# ISD91200B_v1 register map
File version: 1.0
Registers are 32-bit, read-write, reset 0x0 unless marked. A register's access mark holds for its fields unless they carry their own. Offsets are from the block's base; [hi:lo] are bit positions.

## FMC — FMC Register Map
Base 0x5000C000
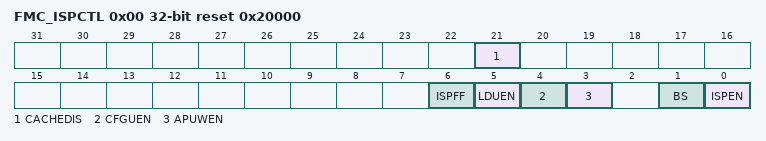
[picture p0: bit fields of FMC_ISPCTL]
0x00 FMC_ISPCTL reset 0x20000 — ISP Control Register
  [21] CACHEDIS — Cache Disable. When set to 1, caching of flash memory reads is disabled.
  [6] ISPFF — ISP Fail Flag. This bit is set by hardware when a triggered ISP meets any of the following conditions: (1) APROM writes to itself. (2) LDROM writes to itself. (3) Destination address is illegal, such as over an available range. Write 1 to clear.
  [5] LDUEN — LDROM Update Enable. LDROM update enable bit.
    0=LDROM cannot be updated; 1=LDROM can be updated when the MCU runs in APROM
  [4] CFGUEN — CONFIG Update Enable. When enabled, ISP functions can access the CONFIG address space and modify device configuration area.
    0=Disable; 1=Enable
  [3] APUWEN — APU Write Enable
    0=APROM can't write itself. ISPFF with "1"; 1=APROM write to itself
  [1] BS — Boot Select. Modify this bit to select which ROM next boot is to occur. This bit also functions as MCU boot status flag, which can be used to check where MCU booted from. This bit is initialized after power-on reset with the inverse of CBS in Config0; It is not reset for any other reset event.
    0=APROM; 1=LDROM
  [0] ISPEN — ISP Enable
    0=Disable ISP function; 1=Enable ISP function
0x04 FMC_ISPADDR — ISP Address Register
  [31:0] ISPADDR — ISP Address Register. This is the memory address register that a subsequent ISP command will access. ISP operation are carried out on 32bit words only, consequently ISPADDR [1:0] must be 00b for correct ISP operation.
0x08 FMC_ISPDAT — ISP Data Register
  [31:0] ISPDAT — ISP Data Register. Write data to this register before an ISP program operation. Read data from this register after an ISP read operation
0x0C FMC_ISPCMD — ISP Command Register
  [5:0] CMD — ISP Command. Operation Mode : CMD. Standby : 0x3X. Read : 0x00. Program : 0x21. Page Erase : 0x22. Read CID : 0x0B. Read DID : 0x0C
0x10 FMC_ISPTRG — ISP Trigger Control Register
  [0] ISPGO — ISP Start Trigger. Write 1 to start ISP operation. This will be cleared to 0 by hardware automatically when ISP operation is finished. After triggering an ISP function M0 instruction pipeline should be flushed with a ISB instruction to guarantee data integrity. This is a protected register, user must first follow the unlock sequence to gain access.
    0=ISP operation is finished; 1=ISP is on going
0x14 FMC_DFBA ro reset not defined — Data Flash Base Address
  [31:0] DFBA — Data Flash Base Address. This register reports the data flash starting address. It is a read only register. Data flash size is defined by user configuration; register content is loaded from Config1 when chip is reset.

## DPWM — DPWM Register Map
Base 0x40070000
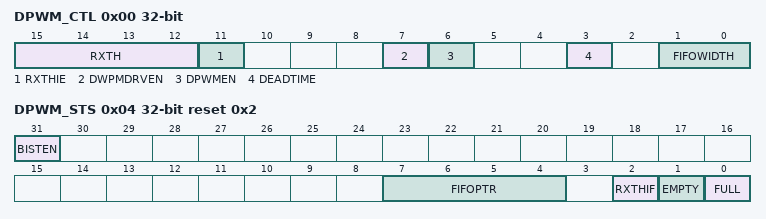
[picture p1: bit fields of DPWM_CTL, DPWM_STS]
0x00 DPWM_CTL — DPWM Control Register
  [15:12] RXTH — DPWM FIFO Threshold. If the valid data count of the DPWM FIFO buffer is less than or equal to RXTH setting, the RXTHIF bit will set to 1, else the RXTHIF bit will be cleared to 0.
  [11] RXTHIE — DPWM FIFO Threshold Interrupt
    0=DPWM FIFO threshold interrupt Disabled; 1=DPWM FIFO threshold interrupt Enabled
  [7] DWPMDRVEN — DPWM Driver Enable
    0=Disable DPWM Driver; 1=Enable DPWM Diver
  [6] DPWMEN — DPWM Enable
    0=Disable DPWM; 1=Enable DPWM
  [3] DEADTIME — DPWM Driver DEADTIME Control. Enabling this bit will insert an additional clock cycle deadtime into the switching of PMOS and NMOS driver transistors.
  [1:0] FIFOWIDTH — DPWM FIFO DATA WIDTH SELETION From PDMA
    0=PDMA MSB 24bits PWDATA[31:8]; 1=PDMA 16 bits PWDATA[15:0]; 2=PDMA 8bits PWDATA[7:0]; 3=PDMA 24bits PWDATA[23:0]
0x04 DPWM_STS ro reset 0x2 — DPWM DATA FIFO Status Register
  [31] BISTEN — BIST Enable. DPWM FIFO can be testing by Cortex-M0. Internal use
    0=disable DPWM FIFO BIST testing; 1=enable DPWM FIFO BIST testing
  [7:4] FIFOPTR — DPWM FIFO Pointer (Read Only). The FULL bit and FIFOPOINTER indicates the field that the valid data count within the DPWM FIFO buffer. The Maximum value shown in FIFO_POINTER is 15. When the using level of DPWM FIFO Buffer equal to 16, The FULL bit is set to 1.
  [2] RXTHIF — DPWM FIFO Threshold Interrupt Status (Read Only)
    0=The valid data count within the DPWM FIFO buffer is larger than the setting value of RXTH; 1=The valid data count within the transmit FIFO buffer is less than or equal to the setting value of RXTH
  [1] EMPTY — FIFO Empty
    0=FIFO is not empty; 1=FIFO is empty
  [0] FULL — FIFO Full
    0=FIFO is not full; 1=FIFO is full
0x08 DPWM_DMACTL — DPWM PDMA Control Register
  [0] DMAEN — Enable DPWM DMA Interface
    0=Disable PDMA. No requests will be made to PDMA controller; 1=Enable PDMA. Block will request data from PDMA controller whenever FIFO is not empty
0x0C DPWM_DATA wo — DPWM DATA FIFO Input
  [31:0] INDATA — DPWM FIFO Audio Data Input. A write to this register pushes data onto the DPWM FIFO and increments the write pointer. This is the address that PDMA writes audio data to.
0x10 DPWM_ZOHDIV reset 0x6 — DPWM Zero Order Hold Division Register
  [2:0] LVL — LVL controls the voltage output of the MICBIAS generator, voltages are encoded as following: 0 - 1.5V1 - 1.8V2 - 1.95V3 - 2.1V4 - 2.25V5 - 2.4V6 - 2.55V 7 - 2.7. Note: MICBIAS voltage should be at least 300mV lower than VCCA.
